# ATUC128D4 device description
Architecture: AVR32_UC3; Family: AVR UC3
Registers are 32-bit, read-write, reset 0x0 unless marked. A register's access mark holds for its fields unless they carry their own. Offsets are from the block's base; [hi:lo] are bit positions; lines under a group give offsets from that group; {n}, {i} and the like mark numbered series; 'fields as' and 'values as' point back to an identical list.

## FREQM — Frequency Meter
Instances: FREQM 0xffff5c00
0x00 CTRL wo — Control register
  [0] START — Start frequency measurement
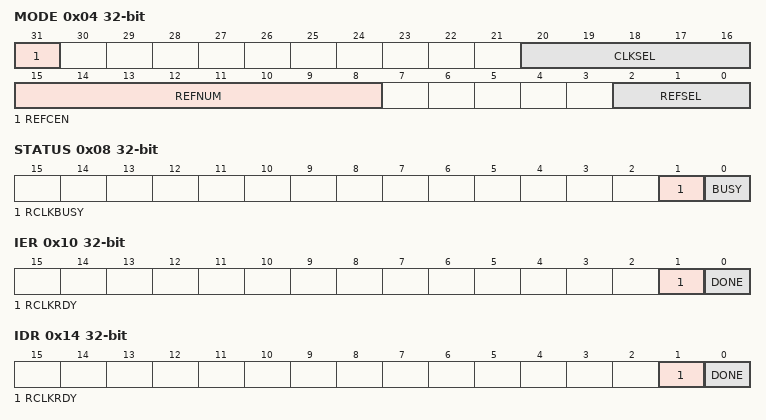
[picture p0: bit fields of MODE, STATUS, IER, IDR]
0x04 MODE
  [31] REFCEN — Reference Clock Enable
  [20:16] CLKSEL — Clock Source Selection
  [15:8] REFNUM — Number of Reference CLock Cycles
  [2:0] REFSEL — Reference Clock Selection
0x08 STATUS ro
  [1] RCLKBUSY — Reference Clock Busy
  [0] BUSY — Frequency measurement on-going
0x0C VALUE ro
  [23:0] VALUE — Measured frequency
0x10 IER wo — Interrupt Enable Register
  [1] RCLKRDY — Reference Clock ready
  [0] DONE — Frequency measurment done
0x14 IDR wo — Interrupt Diable Register
  fields as IER
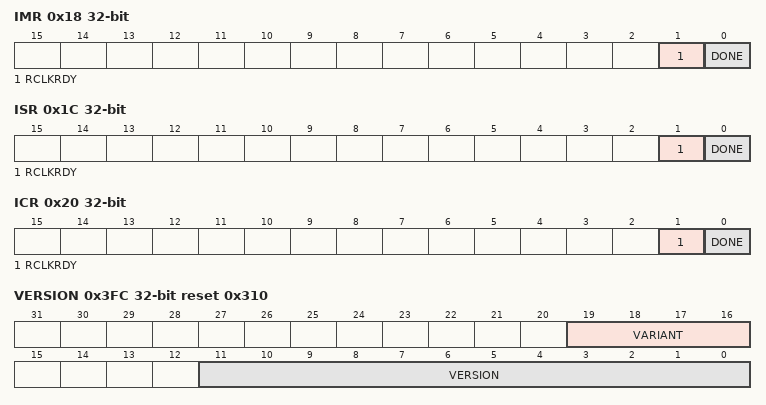
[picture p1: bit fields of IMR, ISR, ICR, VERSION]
0x18 IMR ro — Interrupt Mask Register
  fields as IER
0x1C ISR ro — Interrupt Status Register
  fields as IER
0x20 ICR wo — Interrupt Clear Register
  fields as IER
0x3FC VERSION ro reset 0x310
  [19:16] VARIANT — Variant number
  [11:0] VERSION — Version number

## GLOC — Glue Logic Controller
Instances: GLOC 0xffff6400
{0x0+8i} LUT[{i}] (i=0..6) group
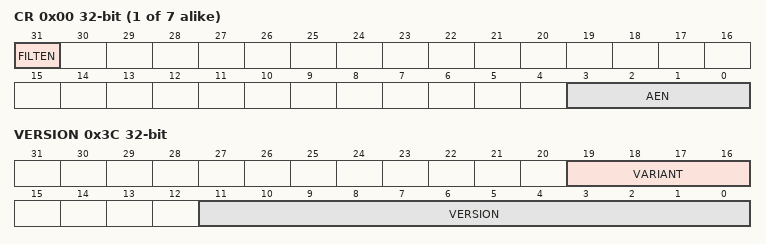
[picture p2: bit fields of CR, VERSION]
  0x00 CR — Control Register
    [31] FILTEN — Filter enable
    [3:0] AEN — Input mask
  0x04 TRUTH
    [15:0] TRUTH
0x38 PARAMETER ro reset not defined
  [7:0] LUTS
0x3C VERSION ro reset not defined
  [19:16] VARIANT, [11:0] VERSION

## GPIO_LOCAL — Local Bus Mapped GPIO Registers
Instances: GPIO_LOCAL 0x40000000
Parameters: PORT_LENGTH=AVR32_GPIO_PORT_LENGTH
{0x0+0x100*i} port[{i}] (i=0..63) group
  0x40 ODERW wo reset not defined — Output Driver Enable Register - Write
  0x44 ODERS wo reset not defined — Output Driver Enable Register - Set
  0x48 ODERC wo reset not defined — Output Driver Enable Register - Clear
  0x4C ODERT wo reset not defined — Output Driver Enable Register - Toggle
  0x50 OVRW wo reset not defined — Output Value Register - Write
  0x54 OVRS wo reset not defined — Output Value Register - Set
  0x58 OVRC wo reset not defined — Output Value Register - Clear
  0x5C OVRT wo reset not defined — Output Value Register - Toggle
  0x60 PVR ro reset not defined — Pin Value Register

## HMATRIXB — HSB Matrix
Instances: HMATRIXB 0xfffe1000
{0x0+4i} mcfg[{i}] (i=0..15) access not given reset 0x2
  [2:0] ULBT — Undefined Length Burst Type
    0=INFINITE; 1=SINGLE; 2=FOUR_BEAT; 3=EIGHT_BEAT; 4=SIXTEEN_BEAT
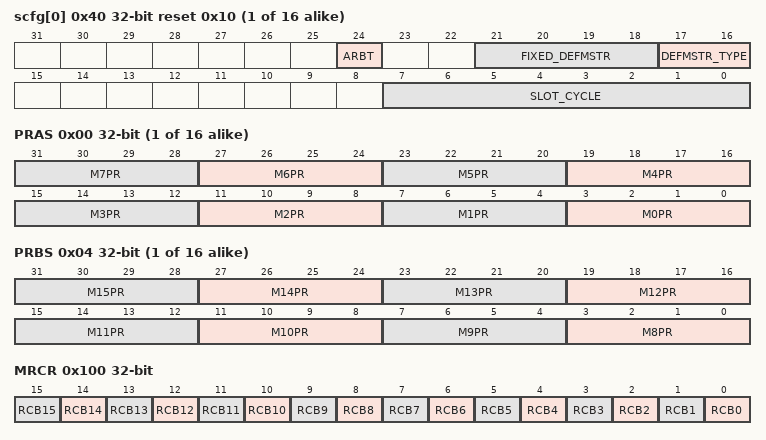
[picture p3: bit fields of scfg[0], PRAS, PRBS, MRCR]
{0x40+4i} scfg[{i}] (i=0..15) access not given reset 0x10
  [24] ARBT — Arbitration Type
    0=ROUND_ROBIN; 1=FIXED_PRIORITY
  [21:18] FIXED_DEFMSTR — Fixed Index of Default Master
  [17:16] DEFMSTR_TYPE — Default Master Type
    0=NO_DEFAULT; 1=LAST_DEFAULT; 2=FIXED_DEFAULT
  [7:0] SLOT_CYCLE — Maximum Number of Allowed Cycles for a Burst
{0x80+8i} prs[{i}] (i=0..15) group
  0x00 PRAS — Priority Register A for Slave 0
    [4n+3:4n] M{n}PR (n=0..7) — Master {n} Priority
  0x04 PRBS — Priority Register B for Slave 0
    [4n-29:4n-32] M{n}PR (n=8..15) — Master {n} Priority
0x100 MRCR — Master Remap Control Register
  [n] RCB{n} (n=0..15) — Remap Command bit for Master {n}
{0x110+4i} sfr[{i}] (i=0..15) access not given
  [31:0] SFR — Special Function Register

## IISC — Inter-IC Sound (I2S) Controller
Instances: IISC 0xffff4c00
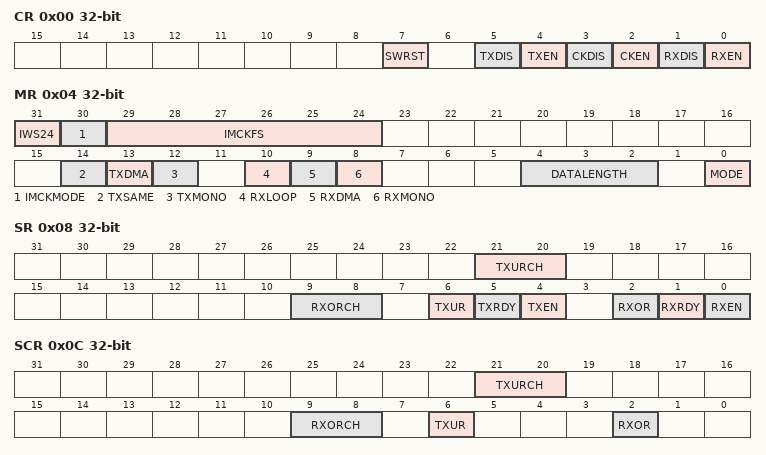
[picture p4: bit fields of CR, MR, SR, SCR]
0x00 CR wo reset not defined — Control Register
  [all] fields
    0=OFF; 1=ON
  [7] SWRST — Software Reset
  [5] TXDIS — Transmit Disable
  [4] TXEN — Transmit Enable
  [3] CKDIS — Clocks Disable
  [2] CKEN — Clocks Enable
  [1] RXDIS — Receive Disable
  [0] RXEN — Receive Enable
0x04 MR — Mode Register
  [31] IWS24 — IWS Data Slot Width
    0=32; 1=24
  [30] IMCKMODE — Master Clock Mode
    0=NO_IMCK; 1=IMCK
  [29:24] IMCKFS — Master Clock to fs Ratio
    0=16; 1=32; 3=64; 7=128; 15=256; 23=384; 31=512; 47=768; 63=1024
  [14] TXSAME — Transmit Data when Underrun
    0=ZERO; 1=SAME
  [13] TXDMA — Single or Multiple DMA Channels for Transmitter
    0=SINGLE; 1=MULTIPLE
  [12] TXMONO — Transmitter Mono
    0=STEREO; 1=MONO
  [10] RXLOOP — Loop-back Test Mode
    0=OFF; 1=ON
  [9] RXDMA — Single or Multiple DMA Channels for Receiver
    0=SINGLE; 1=MULTIPLE
  [8] RXMONO — Receiver Mono
    0=STEREO; 1=MONO
  [4:2] DATALENGTH — Data Word Length
    0=32; 1=24; 2=20; 3=18; 4=16; 5=16C; 6=8; 7=8C
  [0] MODE — Master/Slave/Controller Mode
    0=SLAVE; 1=MASTER
0x08 SR ro — Status Register
  [21:20] TXURCH — Transmit Underrun Channels
    0=LEFT; 1=RIGHT
  [9:8] RXORCH — Receive Overrun Channels
    0=LEFT; 1=RIGHT
  [6] TXUR — Transmit Underrun
    0=NO; 1=SET
  [5] TXRDY — Transmit Ready
    0=FULL; 1=EMPTY
  [4] TXEN — Transmit Enable
    0=OFF; 1=ON
  [2] RXOR — Receive Overrun
    0=NO; 1=SET
  [1] RXRDY — Receive Ready
    0=EMPTY; 1=FULL
  [0] RXEN — Receive Enable
    0=OFF; 1=ON
0x0C SCR wo reset not defined — Status Clear Register
  [21:20] TXURCH — Transmit Underrun Channels
  [9:8] RXORCH — Receive Overrun Channels
  [6] TXUR — Transmit Underrun
    0=NO; 1=SET
  [2] RXOR — Receive Overrun
    0=NO; 1=SET
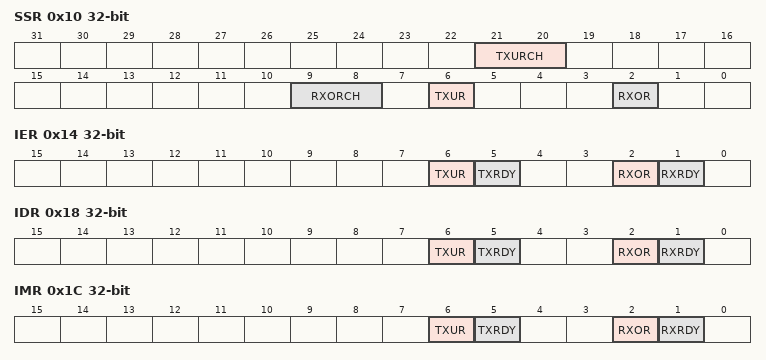
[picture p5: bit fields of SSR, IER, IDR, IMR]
0x10 SSR wo reset not defined — Status Set Register
  fields as SCR
0x14 IER wo reset not defined — Interrupt Enable Register
  [6] TXUR — Transmit Underrun Interrupt Enable
    0=NO; 1=SET
  [5] TXRDY — Transmit Ready Interrupt Enable
    0=FULL; 1=EMPTY
  [2] RXOR — Receive Overrun Interrupt Enable
    0=NO; 1=SET
  [1] RXRDY — Receiver Ready Interrupt Enable
    0=EMPTY; 1=FULL
0x18 IDR wo reset not defined — Interrupt Disable Register
  [6] TXUR — Transmit Underrun Interrupt Disable
    0=NO; 1=SET
  [5] TXRDY — Transmit Ready Interrupt Disable
    0=FULL; 1=EMPTY
  [2] RXOR — Receive Overrun Interrupt Disable
    0=NO; 1=SET
  [1] RXRDY — Receive Ready Interrupt Disable
    0=EMPTY; 1=FULL
0x1C IMR ro — Interrupt Mask Register
  [6] TXUR — Transmit Underrun Interrupt Mask
    0=NO; 1=SET
  [5] TXRDY — Transmit Ready Interrupt Mask
    0=FULL; 1=EMPTY
  [2] RXOR — Receive Overrun Interrupt Mask
    0=NO; 1=SET
  [1] RXRDY — Receive Ready Interrupt Mask
    0=EMPTY; 1=FULL
0x20 RHR ro — Receive Holding Register
  [31:0] RDAT — Receive Data
0x24 THR wo reset not defined — Transmit Holding Register
  [31:0] TDAT — Transmit Data
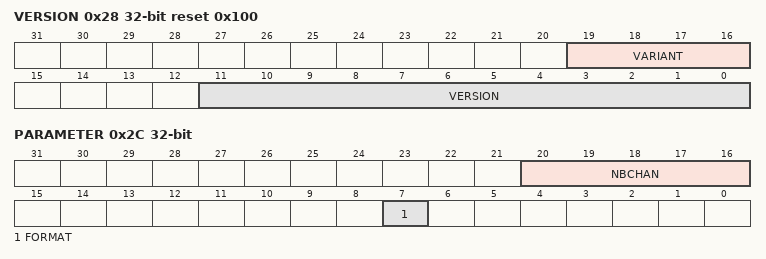
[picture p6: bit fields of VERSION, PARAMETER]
0x28 VERSION ro reset 0x100
  [19:16] VARIANT — Reserved. Value subject to change. No functionality associated.
  [11:0] VERSION — Reserved. Value subject to change. No functionality associated. This is the Atmel internal version of the macrocell.
0x2C PARAMETER ro reset not defined
  [20:16] NBCHAN — Maximum number of channels - 1
  [7] FORMAT — Data protocol format
    0=I2S
